# STM32WB55_CM0P register map
File version: 2.1
CPU: CM0 r0p1, little endian, MPU, no FPU, 4 interrupt priority bits
Registers are 32-bit, read-write, reset 0x0 unless marked. A register's access mark holds for its fields unless they carry their own. Offsets are from the block's base; [hi:lo] are bit positions; {n}, {i} and the like mark numbered series; 'fields as' and 'values as' point back to an identical list.

## RNG — Random number generator
Base 0x58001000
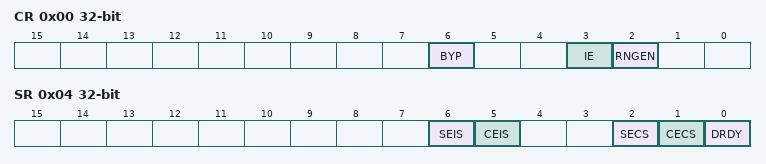
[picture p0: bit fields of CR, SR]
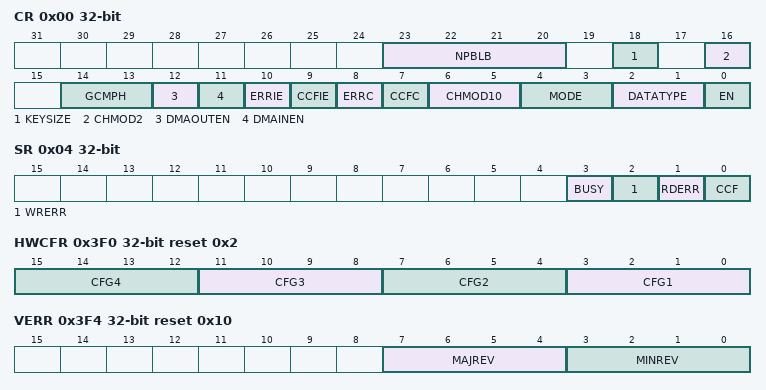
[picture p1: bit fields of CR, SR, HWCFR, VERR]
0x00 CR — control register
  [6] BYP — Bypass mode enable
  [3] IE — Interrupt enable
  [2] RNGEN — Random number generator enable
0x04 SR access per field — status register
  [6] SEIS rw — Seed error interrupt status
  [5] CEIS rw — Clock error interrupt status
  [2] SECS ro — Seed error current status
  [1] CECS ro — Clock error current status
  [0] DRDY ro — Data ready
0x08 DR ro — data register
  [31:0] RNDATA — Random data

## AES1 — Advanced encryption standard hardware accelerator 1
Base 0x50060000
0x00 CR — control register
  [23:20] NPBLB — Number of padding bytes in last block of payload
  [18] KEYSIZE — Key size selection
  [16] CHMOD2 — AES chaining mode Bit2
  [14:13] GCMPH — Used only for GCM, CCM and GMAC algorithms and has no effect when other algorithms are selected
  [12] DMAOUTEN — Enable DMA management of data output phase
  [11] DMAINEN — Enable DMA management of data input phase
  [10] ERRIE — Error interrupt enable
  [9] CCFIE — CCF flag interrupt enable
  [8] ERRC — Error clear
  [7] CCFC — Computation Complete Flag Clear
  [6:5] CHMOD10 — AES chaining mode Bit1 Bit0
  [4:3] MODE — AES operating mode
  [2:1] DATATYPE — Data type selection (for data in and data out to/from the cryptographic block)
  [0] EN — AES enable
0x04 SR ro — status register
  [3] BUSY — Busy flag
  [2] WRERR — Write error flag
  [1] RDERR — Read error flag
  [0] CCF — Computation complete flag
0x08 DINR — data input register
  [31:0] AES_DINR — Data Input Register
0x0C DOUTR ro — data output register
  [31:0] AES_DOUTR — Data output register
0x10 KEYR0 — key register 0
  [31:0] AES_KEYR0 — Data Output Register (LSB key [31:0])
0x14 KEYR1 — key register 1
  [31:0] AES_KEYR1 — AES key register (key [63:32])
0x18 KEYR2 — key register 2
  [31:0] AES_KEYR2 — AES key register (key [95:64])
0x1C KEYR3 — key register 3
  [31:0] AES_KEYR3 — AES key register (MSB key [127:96])
0x20 IVR0 — initialization vector register 0
  [31:0] AES_IVR0 — initialization vector register (LSB IVR [31:0])
0x24 IVR1 — initialization vector register 1
  [31:0] AES_IVR1 — Initialization Vector Register (IVR [63:32])
0x28 IVR2 — initialization vector register 2
  [31:0] AES_IVR2 — Initialization Vector Register (IVR [95:64])
0x2C IVR3 — initialization vector register 3
  [31:0] AES_IVR3 — Initialization Vector Register (MSB IVR [127:96])
{0x20+4i} KEYR{i} (i=4..7) — key register {i}
  [31:0] AES_KEYR{i} — AES key register (MSB key [{32i+31}:{32i}])
{0x40+4i} SUSP{i}R (i=0..7) — AES suspend register {i}
  [31:0] AES_SUSP{i}R
0x3F0 HWCFR ro reset 0x2 — AES hardware configuration register
  [4n-1:4n-4] CFG{n} (n=1..4) — HW Generic {n}
0x3F4 VERR ro reset 0x10 — AES version register
  [7:4] MAJREV — Major revision
  [3:0] MINREV — Minor revision
0x3F8 IPIDR ro reset 0x170023 — AES identification register
  [31:0] ID — Identification code
0x3FC SIDR ro reset 0xA3C5DD01 — AES size ID register
  [31:0] ID — Size Identification code

## AES2 — Advanced encryption standard hardware accelerator 1
Base 0x58001800
Registers as AES1, without HWCFR, VERR, IPIDR, SIDR; these are added or differ:
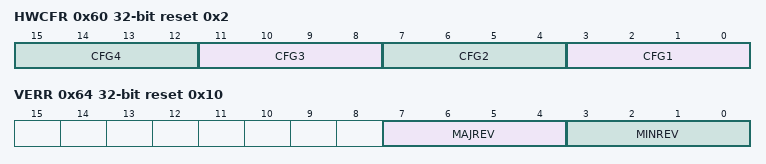
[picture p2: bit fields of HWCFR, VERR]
0x60 HWCFR ro reset 0x2 — AES hardware configuration register
  [4n-1:4n-4] CFG{n} (n=1..4) — HW Generic {n}
0x64 VERR ro reset 0x10 — AES version register
  [7:4] MAJREV — Major revision
  [3:0] MINREV — Minor revision
0x68 IPIDR ro reset 0x170023 — AES identification register
  [31:0] ID — Identification code
0x6C SIDR ro reset 0x170023 — AES size ID register
  [31:0] ID — Size Identification code

## HSEM
Base 0x58001400
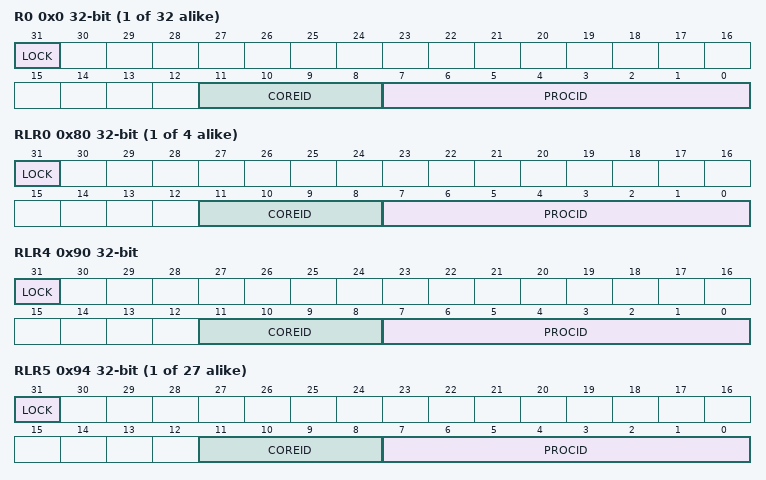
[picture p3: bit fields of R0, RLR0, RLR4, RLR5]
{0x0+4i} R{i} (i=0..31) — Semaphore {i} register
  [31] LOCK — lock indication
  [11:8] COREID — Semaphore CoreID
  [7:0] PROCID — Semaphore ProcessID
{0x80+4i} RLR{i} ro (i=0..3) — Semaphore {i} read lock register
  fields as R0
0x90 RLR4 ro — Semaphore 4 read lock read lock register
  fields as R0
{0x80+4i} RLR{i} ro (i=5..31) — Semaphore {i} read lock register
  fields as R0
0x100 C1IER0 — HSEM Interrupt enable register
  [31:0] ISEm — CPU(n) semaphore m enable bit
0x104 C1ICR — HSEM Interrupt clear register
  [31:0] ISCm — CPU(n) semaphore m clear bit
0x108 C1ISR ro — HSEM Interrupt status register
  [31:0] ISFm — CPU(n) semaphore m status bit before enable (mask)
0x10C C1MISR ro — HSEM Masked interrupt status register
  [31:0] MISFm — masked CPU(n) semaphore m status bit after enable (mask).
0x110 C2IER0 — HSEM Interrupt enable register
  [31:0] ISEm — CPU(2) semaphore m enable bit.
0x114 C2ICR — HSEM Interrupt clear register
  [31:0] ISCm — CPU(2) semaphore m clear bit
0x118 C2ISR ro — HSEM Interrupt status register
  [31:0] ISFm — CPU(2) semaphore m status bit before enable (mask).
0x11C C2MISR ro — HSEM Masked interrupt status register
  [31:0] MISFm — masked CPU(2) semaphore m status bit after enable (mask).
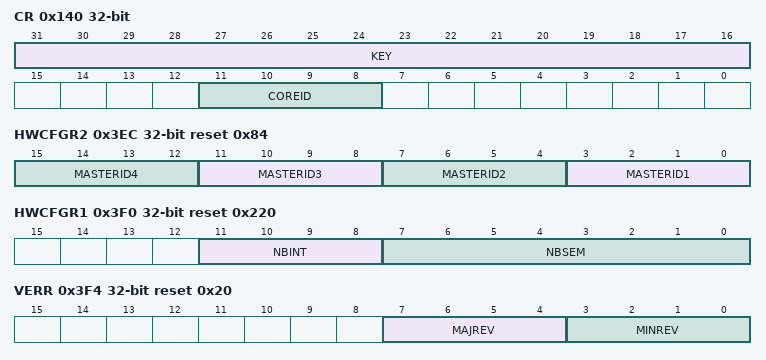
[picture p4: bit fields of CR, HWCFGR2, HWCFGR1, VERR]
0x140 CR — Semaphore Clear register
  [31:16] KEY — Semaphore clear Key
  [11:8] COREID — CoreID of semaphore to be cleared
0x144 KEYR — Interrupt clear register
  [31:16] KEY — Semaphore Clear Key
0x3EC HWCFGR2 ro reset 0x84 — Semaphore hardware configuration register 2
  [4n-1:4n-4] MASTERID{n} (n=1..4) — Hardware Configuration valid bus masters ID{n}
0x3F0 HWCFGR1 ro reset 0x220 — Semaphore hardware configuration register 1
  [11:8] NBINT — Hardware Configuration number of interrupts supported number of master IDs
  [7:0] NBSEM — Hardware Configuration number of semaphores
0x3F4 VERR ro reset 0x20 — HSEM version register
  [7:4] MAJREV — Major Revision
  [3:0] MINREV — Minor Revision
0x3F8 IPIDR ro reset 0x100072 — HSEM indentification register
  [31:0] ID — Identification Code
0x3FC SIDR ro reset 0xA3C5DD01 — HSEM size indentification register
  [31:0] SID — Size Identification Code
